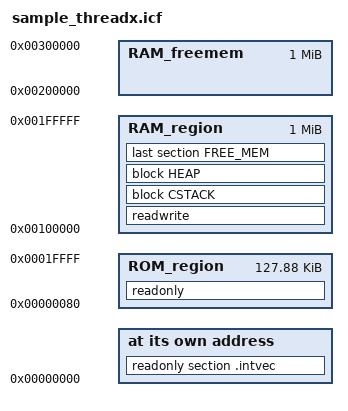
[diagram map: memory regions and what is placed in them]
define symbol __ICFEDIT_intvec_start__ = 0x0;
/*-Memory Regions-*/
define symbol __ICFEDIT_region_ROM_start__   = 0x80;
define symbol __ICFEDIT_region_ROM_end__     = 0x1FFFF;
define symbol __ICFEDIT_region_RAM_start__   = 0x100000;
define symbol __ICFEDIT_region_RAM_end__     = 0x1FFFFF;
/*-Sizes-*/
define symbol __ICFEDIT_size_cstack__   = 0x2000;
define symbol __ICFEDIT_size_heap__     = 0x8000;
/**** End of ICF editor section. ###ICF###*/

define symbol __ICFEDIT_size_freemem__     = 0x100000;


define memory mem with size = 4G;
define region ROM_region   = mem:[from __ICFEDIT_region_ROM_start__   to __ICFEDIT_region_ROM_end__];
define region RAM_region   = mem:[from __ICFEDIT_region_RAM_start__   to __ICFEDIT_region_RAM_end__];
define region RAM_freemem  = mem:[from 0x200000 to 0x300000];

define block CSTACK    with alignment = 8, size = __ICFEDIT_size_cstack__   { };
define block HEAP      with alignment = 8, size = __ICFEDIT_size_heap__     { };


initialize by copy { readwrite };
initialize by copy with packing = none { section __DLIB_PERTHREAD }; // Required in a multi-threaded application
do not initialize  { section .noinit };

place at address mem:__ICFEDIT_intvec_start__ { readonly section .intvec };

place in ROM_region   { readonly };
place in RAM_region   { readwrite,
                        block CSTACK, block HEAP};

place in RAM_region { last section FREE_MEM};
